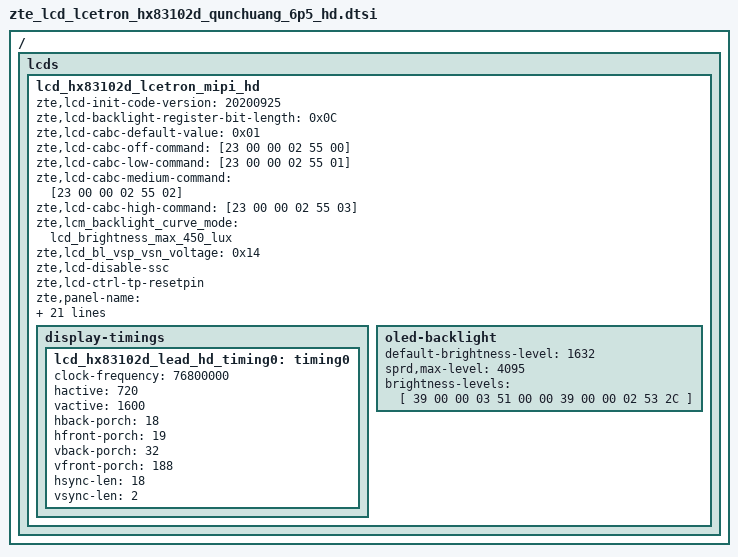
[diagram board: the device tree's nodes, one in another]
/ { lcds {
	lcd_hx83102d_lcetron_mipi_hd: lcd_hx83102d_lcetron_mipi_hd {
		zte,lcd-init-code-version = "20200925";
		zte,lcd-backlight-register-bit-length = <0x0C>;
		zte,lcd-cabc-default-value = <0x01>;
		zte,lcd-cabc-off-command = [23 00 00 02 55 00];
		zte,lcd-cabc-low-command = [23 00 00 02 55 01];
		zte,lcd-cabc-medium-command = [23 00 00 02 55 02];
		zte,lcd-cabc-high-command = [23 00 00 02 55 03];
		zte,lcm_backlight_curve_mode = "lcd_brightness_max_450_lux";
		zte,lcd_bl_vsp_vsn_voltage = <0x14>;
		zte,lcd-disable-ssc;
		zte,lcd-ctrl-tp-resetpin;
		zte,panel-name = "lcd_hx83102d_lcetron_6p517_mipi_hd_himax";

		sprd,dsi-work-mode = <1>; /* video burst mode*/
		sprd,dsi-lane-number = <3>;
		sprd,dsi-color-format = "rgb888";

		sprd,phy-bit-clock = <750000>;	/* kbps */
		sprd,phy-escape-clock = <20000>;/* kHz */

		sprd,width-mm = <67932>;
		sprd,height-mm = <150960>;

		sprd,esd-check-enable = <0>;/* 0:close , 1:open */
		sprd,esd-check-mode = <0>;/* 0:REG ,1:TE  */
		sprd,esd-check-period = <1000>;
		sprd,esd-check-register = <0x0A>;
		sprd,esd-check-value = <0x9C>;

		sprd,reset-on-sequence = <1 5>, <0 5>, <1 35>;
		sprd,reset-off-sequence = <0 5>;
		sprd,initial-command = [
			39 00 00 04 B9 83 10 2D
			39 00 00 0C B1 22 44 2F 2F 22 44 43 57 08 08 08
			39 00 00 0F B2 00 00 06 40 00 0A BC 40 00 00 00 00 14 A0
			39 00 00 0F B4 0C 54 0C 54 0C 54 0C 54 01 FF 01 20 00 FF
			39 00 00 02 CC 02
			39 00 00 1A D3 00 00 3C 01 00 0C 00 3B 37 34 37 20
				00 20 00 32 10 1E 00 00 54 16 64 00 00
			39 00 00 02 BD 01
			39 00 00 04 D3 01 00 7D
			39 00 00 02 BD 00
			39 00 00 2D D5 18 18 18 18 18 18 24 25 1A 1A 1B 1B
				00 01 02 03 04 05 06 07 08 09 0A 0B 20 21 18 18
				18 18 18 18 18 18 18 18 18 18 18 18 18 18 18 18
			39 00 00 18 E7 FF 0F 00 00 1C 1C 0F 0F 17 13 1A 85 00
				85 00 00 00 00 00 00 17 10 68
			39 00 00 02 BD 01
			39 00 00 08 E7 01 2C 01 72 0E 58 0F
			39 00 00 02 BD 00
			39 00 00 2F E0 00 02 08 0C 11 14 27 2C 32 2F 4B 53
				5C 6E 70 7D 8A A3 A8 57 61 70 7F 00 02 08 0C 11
				14 27 2C 32 2F 4B 53 5C 6E 70 7D 8A A3 A8 57 61 70 7F
			39 00 00 14 BA 71 23 A8 8B B2 C0 C0 01 10 00 00 00 0D 3D 82 77 04 01 04
			39 00 00 09 C7 00 C2 00 10 44 00 02 03
			39 00 00 08 BF FC 00 04 9E F6 00 5D
			39 00 00 06 CB 00 13 00 02 5B
			39 00 00 02 BD 01
			39 00 00 02 CB 01
			39 00 00 02 BD 02
			39 00 00 09 B4 42 00 33 00 33 88 B3 00
			39 00 00 04 B1 7F 03 F5
			39 00 00 02 BD 00
			39 00 00 05 C9 04 08 80 01
			39 00 00 03 51 00 00
			39 00 00 02 53 24
			39 00 00 02 55 01
			05 64 00 01 11
			05 0A 00 01 29
			];
		sprd,sleep-in-command = [
			13 0A 00 01 28
			13 78 00 01 10
			];
		sprd,sleep-out-command = [
			13 64 00 01 11
			13 0A 00 01 29
			];

		display-timings {
			lcd_hx83102d_lead_hd_timing0: timing0 {
			clock-frequency = <76800000>;
			hactive = <720>;
			vactive = <1600>;
			hback-porch = <18>;
			hfront-porch = <19>;
			vback-porch = <32>;
			vfront-porch = <188>;
			hsync-len = <18>;
			vsync-len = <2>;
			};
		};

		oled-backlight {
			default-brightness-level = <1632>;
			sprd,max-level = <4095>;
			brightness-levels = [
				39 00 00 03 51 00 00
				39 00 00 02 53 2C
			];
		};
	};
};};

